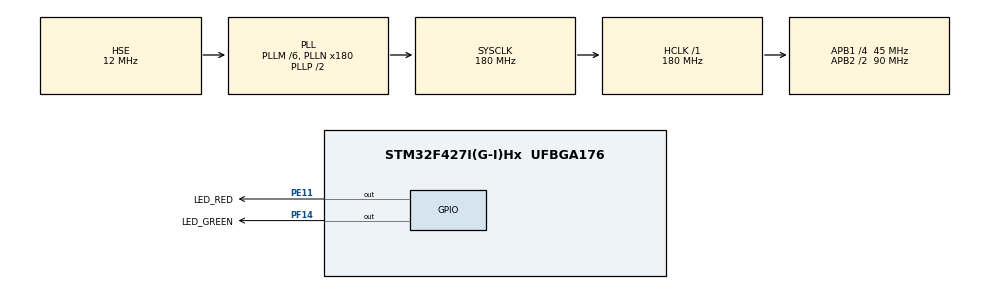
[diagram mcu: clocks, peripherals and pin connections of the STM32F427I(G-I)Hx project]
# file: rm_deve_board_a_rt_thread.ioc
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Mcu.Family=STM32F4
Mcu.Name=STM32F427I(G-I)Hx
Mcu.Package=UFBGA176
NVIC.PriorityGroup=NVIC_PRIORITYGROUP_4
PA13.Mode=Serial_Wire
PA13.Signal=SYS_JTMS-SWDIO
PA14.Mode=Serial_Wire
PA14.Signal=SYS_JTCK-SWCLK
PE11.GPIO_Label=LED_RED
PE11.GPIO_PuPd=GPIO_PULLUP
PE11.GPIO_Speed=GPIO_SPEED_FREQ_MEDIUM
PE11.PinState=GPIO_PIN_SET
PE11.Signal=GPIO_Output
PF14.GPIO_Label=LED_GREEN
PF14.GPIO_PuPd=GPIO_PULLUP
PF14.GPIO_Speed=GPIO_SPEED_FREQ_MEDIUM
PF14.PinState=GPIO_PIN_SET
PF14.Signal=GPIO_Output
PH0/OSC_IN.Mode=HSE-External-Oscillator
PH0/OSC_IN.Signal=RCC_OSC_IN
PH1/OSC_OUT.Mode=HSE-External-Oscillator
PH1/OSC_OUT.Signal=RCC_OSC_OUT
ProjectManager.HeapSize=0x200
ProjectManager.StackSize=0x400
ProjectManager.TargetToolchain=Makefile
RCC.48MHZClocksFreq_Value=90000000
RCC.AHBFreq_Value=180000000
RCC.APB1CLKDivider=RCC_HCLK_DIV4
RCC.APB1Freq_Value=45000000
RCC.APB1TimFreq_Value=90000000
RCC.APB2CLKDivider=RCC_HCLK_DIV2
RCC.APB2Freq_Value=90000000
RCC.APB2TimFreq_Value=180000000
RCC.CortexFreq_Value=180000000
RCC.HCLKFreq_Value=180000000
RCC.HSE_VALUE=12000000
RCC.HSI_VALUE=16000000
RCC.LSE_VALUE=32768
RCC.PLLM=6
RCC.PLLN=180
RCC.PLLSourceVirtual=RCC_PLLSOURCE_HSE
RCC.SYSCLKFreq_VALUE=180000000
RCC.SYSCLKSource=RCC_SYSCLKSOURCE_PLLCLK
RCC.VCOOutputFreq_Value=360000000
board=custom

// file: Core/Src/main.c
/* USER CODE BEGIN Header */
/**
  ******************************************************************************
  * @file         \rt_thread_rm_board\rm_deve_board_a_rt_thread\Core\Src\main.c
  * @brief          : Main program body
  ******************************************************************************
  * @attention
  *
  * <h2><center>&copy; Copyright (c) 2021 STMicroelectronics.
  * All rights reserved.</center></h2>
  *
  * This software component is licensed by ST under BSD 3-Clause license,
  * the "License"; You may not use this file except in compliance with the
  * License. You may obtain a copy of the License at:
  *                        opensource.org/licenses/BSD-3-Clause
  *
  ******************************************************************************
  */
/* USER CODE END Header */
#include "main.h"
#include "gpio.h"

/* USER CODE BEGIN Includes */
#include <rtthread.h>
/* USER CODE END Includes */

void SystemClock_Config(void);

int main(void)
{

  /* MCU Configuration--------------------------------------------------------*/

  /* Reset of all peripherals, Initializes the Flash interface and the Systick. */
  HAL_Init();

  /* Configure the system clock */
  SystemClock_Config();

  /* Initialize all configured peripherals */
  MX_GPIO_Init();

  /* Infinite loop */
  while (1)
  {

    /* USER CODE BEGIN 3 */
        HAL_GPIO_TogglePin(LED_GREEN_GPIO_Port, LED_GREEN_Pin);
        HAL_GPIO_TogglePin(LED_RED_GPIO_Port, LED_RED_Pin);
        rt_thread_mdelay(500);
  }
  /* USER CODE END 3 */
}

void SystemClock_Config(void)
{
  RCC_OscInitTypeDef RCC_OscInitStruct = {0};
  RCC_ClkInitTypeDef RCC_ClkInitStruct = {0};

  /** Configure the main internal regulator output voltage
  */
  __HAL_RCC_PWR_CLK_ENABLE();
  __HAL_PWR_VOLTAGESCALING_CONFIG(PWR_REGULATOR_VOLTAGE_SCALE1);
  /** Initializes the RCC Oscillators according to the specified parameters
  * in the RCC_OscInitTypeDef structure.
  */
  RCC_OscInitStruct.OscillatorType = RCC_OSCILLATORTYPE_HSE;
  RCC_OscInitStruct.HSEState = RCC_HSE_ON;
  RCC_OscInitStruct.PLL.PLLState = RCC_PLL_ON;
  RCC_OscInitStruct.PLL.PLLSource = RCC_PLLSOURCE_HSE;
  RCC_OscInitStruct.PLL.PLLM = 6;
  RCC_OscInitStruct.PLL.PLLN = 180;
  RCC_OscInitStruct.PLL.PLLP = RCC_PLLP_DIV2;
  RCC_OscInitStruct.PLL.PLLQ = 4;
  if (HAL_RCC_OscConfig(&RCC_OscInitStruct) != HAL_OK)
  {
    Error_Handler();
  }
  /** Activate the Over-Drive mode
  */
  if (HAL_PWREx_EnableOverDrive() != HAL_OK)
  {
    Error_Handler();
  }
  /** Initializes the CPU, AHB and APB buses clocks
  */
  RCC_ClkInitStruct.ClockType = RCC_CLOCKTYPE_HCLK|RCC_CLOCKTYPE_SYSCLK
                              |RCC_CLOCKTYPE_PCLK1|RCC_CLOCKTYPE_PCLK2;
  RCC_ClkInitStruct.SYSCLKSource = RCC_SYSCLKSOURCE_PLLCLK;
  RCC_ClkInitStruct.AHBCLKDivider = RCC_SYSCLK_DIV1;
  RCC_ClkInitStruct.APB1CLKDivider = RCC_HCLK_DIV4;
  RCC_ClkInitStruct.APB2CLKDivider = RCC_HCLK_DIV2;

  if (HAL_RCC_ClockConfig(&RCC_ClkInitStruct, FLASH_LATENCY_5) != HAL_OK)
  {
    Error_Handler();
  }
}

void Error_Handler(void)
{
  __disable_irq();
  while (1)
  {
  }
}

/************************ (C) COPYRIGHT STMicroelectronics *****END OF FILE****/
